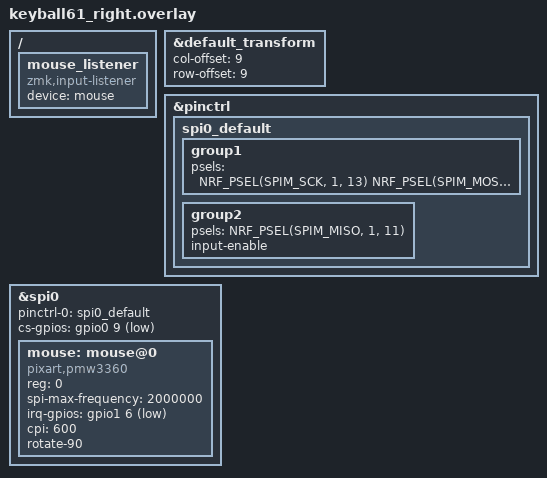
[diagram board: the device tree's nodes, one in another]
#include "keyball61.dtsi"
#include <dt-bindings/pinctrl/nrf-pinctrl.h>

&default_transform {
    col-offset = <9>;
    row-offset = <9>;
};

&pinctrl {
    spi0_default: spi0_default {
        group1
        {
            psels = <
                NRF_PSEL(SPIM_SCK,  1, 13)
                NRF_PSEL(SPIM_MOSI, 0, 10)
                NRF_PSEL(SPIM_CSN,  0,  9)
            >;
        };

        group2 {
            psels = <NRF_PSEL(SPIM_MISO, 1, 11)>;
            input-enable;
        };
    };
};


&spi0 {
    status = "okay";
    pinctrl-0 = <&spi0_default>;
    pinctrl-names = "default";
    cs-gpios = <&gpio0 9 GPIO_ACTIVE_LOW>;
	mouse: mouse@0 {
		compatible = "pixart,pmw3360";
		status = "okay";
		reg = <0>;
		spi-max-frequency = <2000000>;

		// pmw3360 driver parameters
		irq-gpios = <&gpio1 6 (GPIO_ACTIVE_LOW | GPIO_PULL_UP)>;
		cpi = <600>;
		rotate-90;
	};
};

/ {
	mouse_listener {
		compatible = "zmk,input-listener";
		device = <&mouse>;
	};
};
